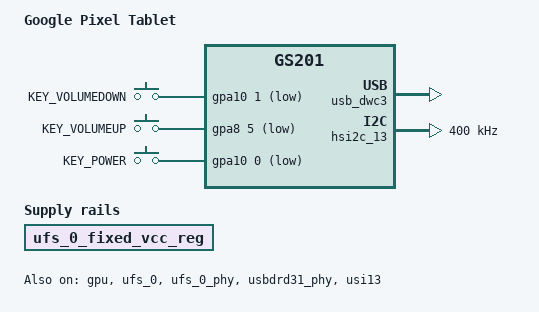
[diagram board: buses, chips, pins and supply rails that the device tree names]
// SPDX-License-Identifier: GPL-2.0-only
/*
 * Google Pixel Tablet (tangorpro) - first-light board file.
 *
 * USB (NCM + ACM), the cluster watchdogs from gs201.dtsi, a
 * simple-framebuffer on the buffer the bootloader leaves the panel
 * scanning out, UFS, the three keys, the GPU and the MAX77759's I2C bus.
 * The panel driver, backlight and touch stay disabled. The tablet has no
 * modem.
 */

/dts-v1/;

#include <dt-bindings/input/input.h>
#include "gs201.dtsi"

/ {
	model = "Google Pixel Tablet";
	compatible = "google,gs201-tangorpro", "google,gs201";

	/*
	 * ABL's base-DTB match: product id 0x09855000 | major revision (B0 is
	 * 1), as on the other gs201 Pixels.
	 */
	soc_id = <0x09855001 0x0>;

	chosen {
		/* ABL requires bootargs to exist; it appends its own after these. */
		bootargs = "console=tty0 panic=10 reboot=warm clk_ignore_unused pd_ignore_unused rdinit=/init omamobile.ufs-probe";
		#address-cells = <2>;
		#size-cells = <1>;
		ranges;

		/*
		 * ABL hands the display over at 0xfac00000 (the 20 MiB
		 * fb_handover region in Google's tangorpro display tree). The
		 * LCD runs in DSI video mode, so DECON keeps scanning the
		 * buffer with no trigger. There is no panel driver, so no panel
		 * phandle; the size comes from this node: 1600 x 2560
		 * portrait, ARGB8888 assumed as on panther until DPP0's
		 * registers are read on this tablet.
		 */
		framebuffer0: framebuffer@fac00000 {
			compatible = "simple-framebuffer";
			reg = <0x0 0xfac00000 (1600 * 2560 * 4)>;
			memory-region = <&cont_splash_mem>;
			width = <1600>;
			height = <2560>;
			stride = <(1600 * 4)>;
			format = "a8r8g8b8";
		};
	};

	/*
	 * Google's shared gs201-common.dtsi pins, which tangorpro does not
	 * override: the same as panther's and cheetah's.
	 */
	gpio-keys {
		compatible = "gpio-keys";
		pinctrl-0 = <&key_voldown>, <&key_volup>, <&key_power>;
		pinctrl-names = "default";

		button-vol-down {
			label = "KEY_VOLUMEDOWN";
			linux,code = <KEY_VOLUMEDOWN>;
			gpios = <&gpa10 1 GPIO_ACTIVE_LOW>;
			wakeup-source;
		};

		button-vol-up {
			label = "KEY_VOLUMEUP";
			linux,code = <KEY_VOLUMEUP>;
			gpios = <&gpa8 5 GPIO_ACTIVE_LOW>;
			wakeup-source;
		};

		/*
		 * PMIC_PWRON_OD_L: the S2MPG12 PWRONB line, also wired to the
		 * SoC. The PMIC's own long-press reset is unaffected.
		 */
		button-power {
			label = "KEY_POWER";
			linux,code = <KEY_POWER>;
			gpios = <&gpa10 0 GPIO_ACTIVE_LOW>;
			wakeup-source;
		};
	};

	/*
	 * UFS VCC. Google's shared gs201-ufs.dtsi drives it from GPIO gpp0-1
	 * (boot-on) and tangorpro does not override it; with no gs201 GPIO
	 * regulator wiring here yet, describe it as always on, as the
	 * bootloader leaves it (as on panther).
	 */
	ufs_0_fixed_vcc_reg: regulator-ufs-vcc {
		compatible = "regulator-fixed";
		regulator-name = "ufs-vcc";
		regulator-always-on;
		regulator-boot-on;
	};

	reserved-memory {
		#address-cells = <2>;
		#size-cells = <1>;
		ranges;

		/*
		 * Stock's region and layout (ramoops_mem@fd3ff000 in Google's
		 * gs201-rmem.dtsi, which tangorpro does not override), so a log
		 * from this kernel can be read after a warm reboot into slot A.
		 */
		ramoops@fd3ff000 {
			compatible = "ramoops";
			reg = <0x0 0xfd3ff000 0x400000>;
			console-size = <0x200000>;
			pmsg-size = <0x200000>;
		};

		/* The whole handover region, as stock reserves it. */
		cont_splash_mem: splash@fac00000 {
			reg = <0x0 0xfac00000 0x1400000>;
			no-map;
		};
	};
};

&gpu {
	/* No mali-supply: the G3D rails follow the PMU power domain and ACPM. */
	status = "okay";
};

&ufs_0 {
	vcc-supply = <&ufs_0_fixed_vcc_reg>;
	status = "okay";
};

&ufs_0_phy {
	status = "okay";
};

&usbdrd31_phy {
	status = "okay";
};

&usb_dwc3 {
	status = "okay";
};

/*
 * Touchscreen: the touch half of the panel's Novatek NT36523N touch and
 * display driver chip, on USI0 SPI with the Pixel 7's pins (chip select
 * gpp20-3, interrupt gpa7-0, reset gpp23-2), per Google's GPL
 * gs201-tangorpro-touch.dtsi and gs201-common-touch.dtsi: 15 MHz, 1 us
 * from chip select to the clock (cs-clock-delay), interrupt on the rising
 * edge, no pull on the interrupt or reset lines. It has no supply of its
 * own: Google's tablet tree gives the Pixel 7's touch rails, LDO25M and
 * LDO26M, to the backlight enable and the pogo accessory detect, and its
 * touch driver switches no regulator; the chip runs from the panel's
 * rails, which the bootloader leaves on. Flashless: the driver loads the
 * firmware that matches the panel (BOE here; the CSOT panel takes
 * novatek/nt36523n-tangorpro-csot.bin). Disabled until the touch overlay.
 */
&usi0 {
	samsung,mode = <USI_MODE_SPI>;
};

&spi_0 {
	pinctrl-0 = <&spi0_bus &spi0_miso &spi0_cs_gpio>;
	cs-gpios = <&gpp20 3 GPIO_ACTIVE_LOW>;
	num-cs = <1>;

	touchscreen: touchscreen@0 {
		compatible = "novatek,nt36523-ts";
		reg = <0>;
		spi-max-frequency = <15000000>;
		spi-cs-setup-delay-ns = <1000>;
		interrupt-parent = <&gpa7>;
		interrupts = <0 IRQ_TYPE_EDGE_RISING>;
		reset-gpios = <&gpp23 2 GPIO_ACTIVE_LOW>;
		pinctrl-0 = <&ts_irq &ts_reset>;
		pinctrl-names = "default";
		firmware-name = "novatek/nt36523n-tangorpro-boe.bin";
		touchscreen-size-x = <1600>;
		touchscreen-size-y = <2560>;
		status = "disabled";
	};
};

/*
 * MAX77759 (charger, Type-C port controller, fuel gauge) on USI13, as on
 * the Pixel 7 and Pixel 7 Pro: Google's tablet tree takes it unchanged
 * from gs201-cloudripper-battery.dtsi and gs201-common-typec.dtsi (TCPC
 * 0x25, PMIC 0x66, fuel gauge 0x36, charger 0x69, bus pins gpp25-0/1,
 * 400 kHz). Its devices are not described here: the Type-C port
 * controller would take over VBUS and the data role from the forced-VBUS
 * setup the USB PHY uses, and the USB link is our only way into the
 * tablet.
 */
&usi13 {
	samsung,mode = <USI_MODE_I2C>;
	status = "okay";
};

&hsi2c_13 {
	clock-frequency = <400000>;
	status = "okay";
};
